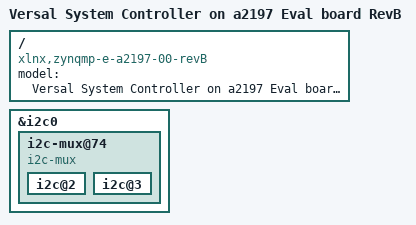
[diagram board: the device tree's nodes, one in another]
// SPDX-License-Identifier: GPL-2.0
/*
 * dts file for Xilinx Versal a2197 RevB System Controller
 *
 * (C) Copyright 2019 - 2022, Xilinx, Inc.
 * (C) Copyright 2022 - 2023, Advanced Micro Devices, Inc.
 *
 * Michal Simek <michal.simek@amd.com>
 */

#include "zynqmp-e-a2197-00-revA.dts"

/ {
	model = "Versal System Controller on a2197 Eval board RevB"; /* VCK190/VMK180 */
	compatible = "xlnx,zynqmp-e-a2197-00-revB", "xlnx,zynqmp-a2197-revB",
		     "xlnx,zynqmp-a2197", "xlnx,zynqmp";

	/delete-node/ ina226-vcco-500;
	/delete-node/ ina226-vcco-501;
	/delete-node/ ina226-vcco-502;
};

&i2c0 {
	i2c-mux@74 { /* u33 */
		i2c@2 { /* PCIE_CLK */
			/delete-node/ clock-generator@6c;
		};
		i2c@3 { /* PMBUS2_INA226 */
			/delete-node/ ina226@42;
			/delete-node/ ina226@43;
			/delete-node/ ina226@44;
		};
	};
};
